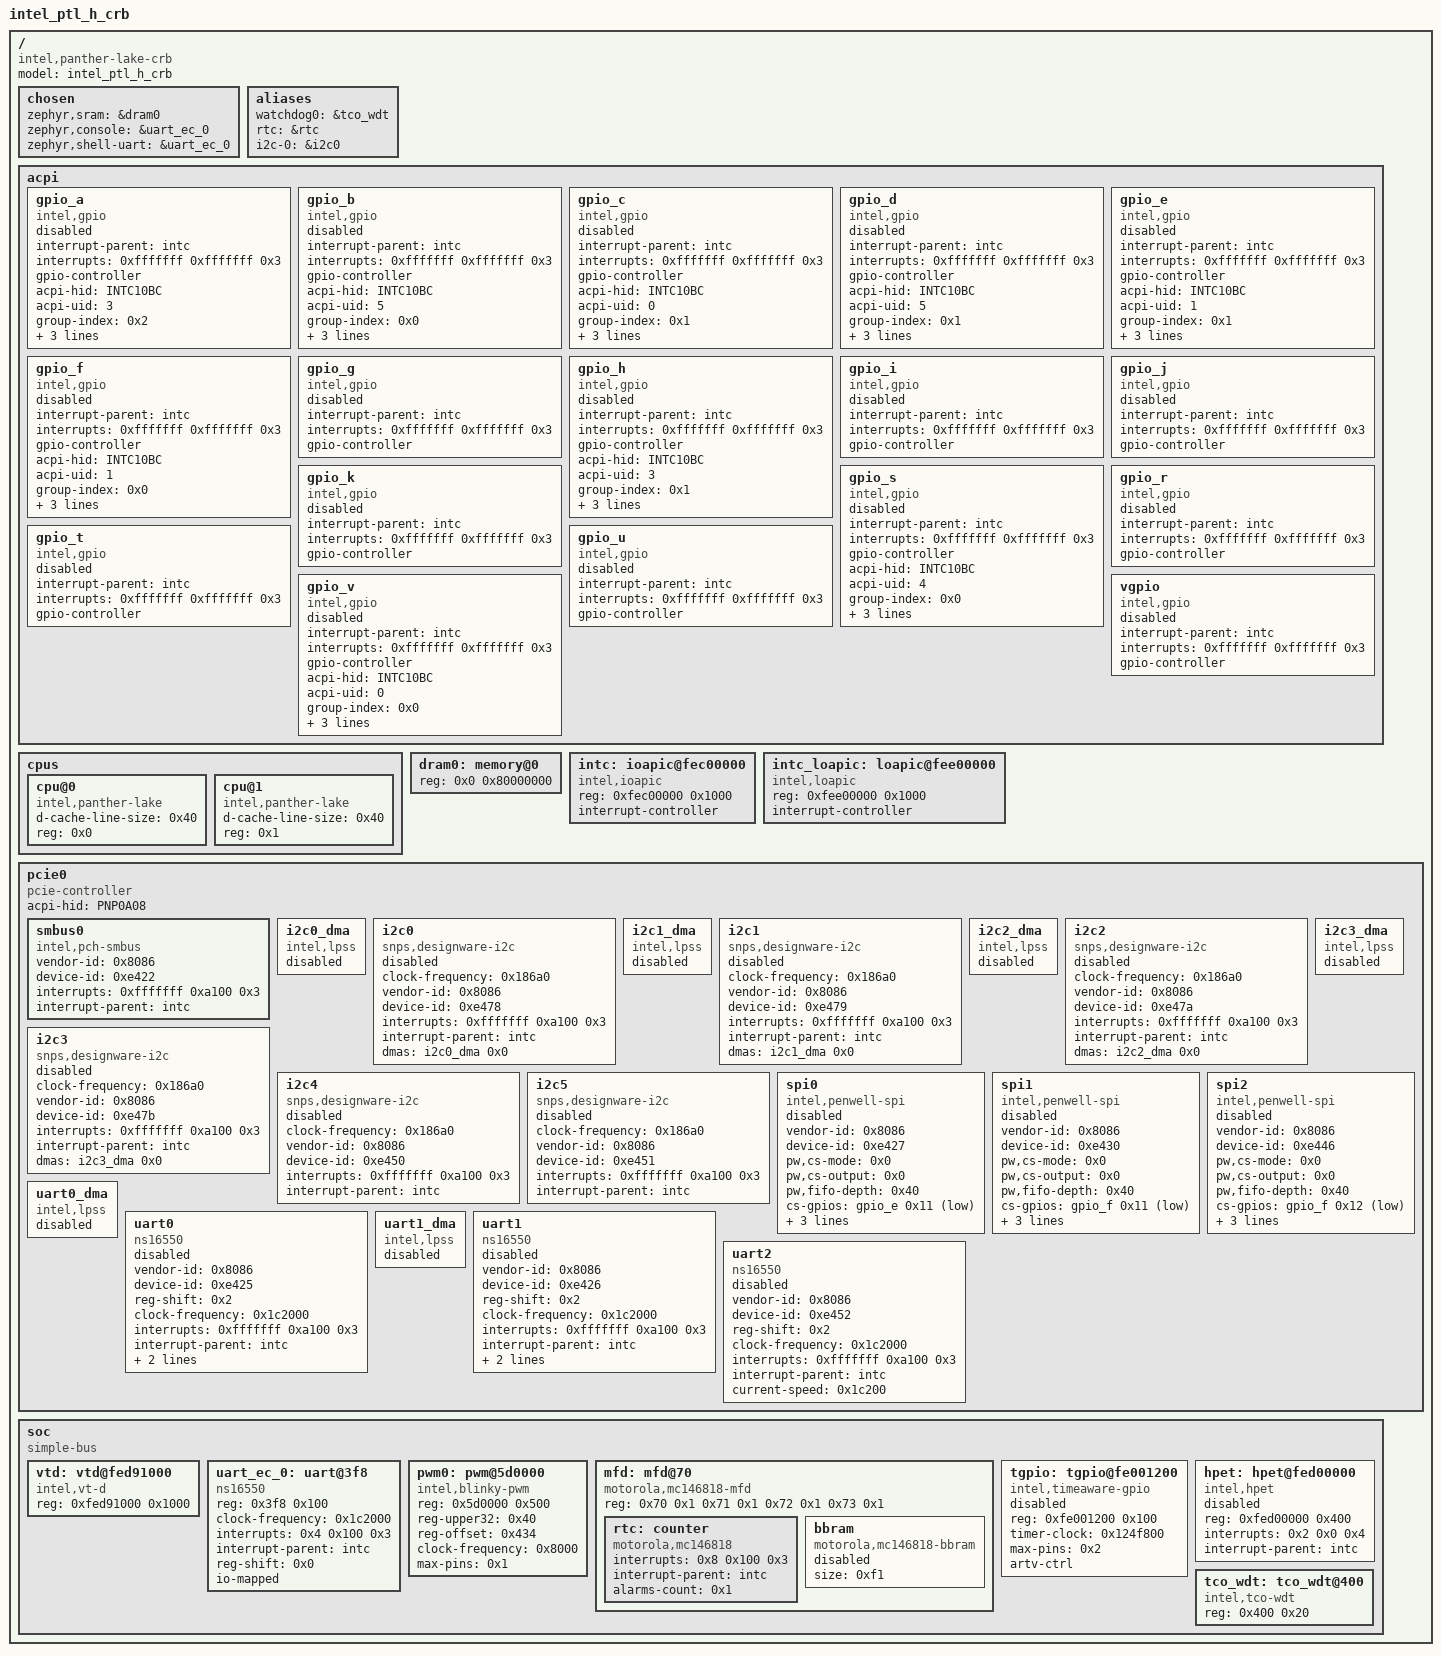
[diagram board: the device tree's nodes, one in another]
/dts-v1/;

/* node '/' defined in zephyr/dts/common/skeleton.dtsi:9 */
/ {
	#address-cells = < 0x1 >;              /* in zephyr/dts/common/skeleton.dtsi:10 */
	#size-cells = < 0x1 >;                 /* in zephyr/dts/common/skeleton.dtsi:11 */
	model = "intel_ptl_h_crb";             /* in zephyr/boards/intel/ptl/intel_ptl_h_crb.dts:15 */
	compatible = "intel,panther-lake-crb"; /* in zephyr/boards/intel/ptl/intel_ptl_h_crb.dts:16 */

	/* node '/chosen' defined in zephyr/dts/common/skeleton.dtsi:13 */
	chosen {
		zephyr,sram = &dram0;           /* in zephyr/boards/intel/ptl/intel_ptl_h_crb.dts:19 */
		zephyr,console = &uart_ec_0;    /* in zephyr/boards/intel/ptl/intel_ptl_h_crb.dts:20 */
		zephyr,shell-uart = &uart_ec_0; /* in zephyr/boards/intel/ptl/intel_ptl_h_crb.dts:21 */
	};

	/* node '/aliases' defined in zephyr/dts/common/skeleton.dtsi:15 */
	aliases {
		watchdog0 = &tco_wdt; /* in zephyr/boards/intel/ptl/intel_ptl_h_crb.dts:25 */
		rtc = &rtc;           /* in zephyr/boards/intel/ptl/intel_ptl_h_crb.dts:26 */
		i2c-0 = &i2c0;        /* in zephyr/boards/intel/ptl/intel_ptl_h_crb.dts:27 */
	};

	/* node '/acpi' defined in zephyr/dts/x86/intel/gpio_common.dtsi:12 */
	acpi {

		/* node '/acpi/gpio_a' defined in zephyr/dts/x86/intel/gpio_common.dtsi:13 */
		gpio_a: gpio_a {
			compatible = "intel,gpio";                /* in zephyr/dts/x86/intel/gpio_common.dtsi:14 */
			interrupt-parent = < &intc >;             /* in zephyr/dts/x86/intel/gpio_common.dtsi:15 */
			interrupts = < 0xfffffff 0xfffffff 0x3 >; /* in zephyr/dts/x86/intel/gpio_common.dtsi:16 */
			gpio-controller;                          /* in zephyr/dts/x86/intel/gpio_common.dtsi:17 */
			#gpio-cells = < 0x2 >;                    /* in zephyr/dts/x86/intel/gpio_common.dtsi:18 */
			acpi-hid = "INTC10BC";                    /* in zephyr/dts/x86/intel/panther_lake_h.dtsi:56 */
			acpi-uid = "3";                           /* in zephyr/dts/x86/intel/panther_lake_h.dtsi:57 */
			group-index = < 0x2 >;                    /* in zephyr/dts/x86/intel/panther_lake_h.dtsi:58 */
			acpi-ginf-3-param;                        /* in zephyr/dts/x86/intel/panther_lake_h.dtsi:59 */
			int-stat-offset = < 0x30 >;               /* in zephyr/dts/x86/intel/panther_lake_h.dtsi:60 */
			int-en-offset = < 0x20 >;                 /* in zephyr/dts/x86/intel/panther_lake_h.dtsi:61 */
			status = "disabled";                      /* in zephyr/dts/x86/intel/panther_lake_h.dtsi:62 */
		};

		/* node '/acpi/gpio_b' defined in zephyr/dts/x86/intel/gpio_common.dtsi:22 */
		gpio_b: gpio_b {
			compatible = "intel,gpio";                /* in zephyr/dts/x86/intel/gpio_common.dtsi:23 */
			interrupt-parent = < &intc >;             /* in zephyr/dts/x86/intel/gpio_common.dtsi:24 */
			interrupts = < 0xfffffff 0xfffffff 0x3 >; /* in zephyr/dts/x86/intel/gpio_common.dtsi:25 */
			gpio-controller;                          /* in zephyr/dts/x86/intel/gpio_common.dtsi:26 */
			#gpio-cells = < 0x2 >;                    /* in zephyr/dts/x86/intel/gpio_common.dtsi:27 */
			acpi-hid = "INTC10BC";                    /* in zephyr/dts/x86/intel/panther_lake_h.dtsi:66 */
			acpi-uid = "5";                           /* in zephyr/dts/x86/intel/panther_lake_h.dtsi:67 */
			group-index = < 0x0 >;                    /* in zephyr/dts/x86/intel/panther_lake_h.dtsi:68 */
			acpi-ginf-3-param;                        /* in zephyr/dts/x86/intel/panther_lake_h.dtsi:69 */
			int-stat-offset = < 0x30 >;               /* in zephyr/dts/x86/intel/panther_lake_h.dtsi:70 */
			int-en-offset = < 0x20 >;                 /* in zephyr/dts/x86/intel/panther_lake_h.dtsi:71 */
			status = "disabled";                      /* in zephyr/dts/x86/intel/panther_lake_h.dtsi:72 */
		};

		/* node '/acpi/gpio_c' defined in zephyr/dts/x86/intel/gpio_common.dtsi:31 */
		gpio_c: gpio_c {
			compatible = "intel,gpio";                /* in zephyr/dts/x86/intel/gpio_common.dtsi:32 */
			interrupt-parent = < &intc >;             /* in zephyr/dts/x86/intel/gpio_common.dtsi:33 */
			interrupts = < 0xfffffff 0xfffffff 0x3 >; /* in zephyr/dts/x86/intel/gpio_common.dtsi:34 */
			gpio-controller;                          /* in zephyr/dts/x86/intel/gpio_common.dtsi:35 */
			#gpio-cells = < 0x2 >;                    /* in zephyr/dts/x86/intel/gpio_common.dtsi:36 */
			acpi-hid = "INTC10BC";                    /* in zephyr/dts/x86/intel/panther_lake_h.dtsi:76 */
			acpi-uid = "0";                           /* in zephyr/dts/x86/intel/panther_lake_h.dtsi:77 */
			group-index = < 0x1 >;                    /* in zephyr/dts/x86/intel/panther_lake_h.dtsi:78 */
			acpi-ginf-3-param;                        /* in zephyr/dts/x86/intel/panther_lake_h.dtsi:79 */
			int-stat-offset = < 0x30 >;               /* in zephyr/dts/x86/intel/panther_lake_h.dtsi:80 */
			int-en-offset = < 0x20 >;                 /* in zephyr/dts/x86/intel/panther_lake_h.dtsi:81 */
			status = "disabled";                      /* in zephyr/dts/x86/intel/panther_lake_h.dtsi:82 */
		};

		/* node '/acpi/gpio_d' defined in zephyr/dts/x86/intel/gpio_common.dtsi:40 */
		gpio_d: gpio_d {
			compatible = "intel,gpio";                /* in zephyr/dts/x86/intel/gpio_common.dtsi:41 */
			interrupt-parent = < &intc >;             /* in zephyr/dts/x86/intel/gpio_common.dtsi:42 */
			interrupts = < 0xfffffff 0xfffffff 0x3 >; /* in zephyr/dts/x86/intel/gpio_common.dtsi:43 */
			gpio-controller;                          /* in zephyr/dts/x86/intel/gpio_common.dtsi:44 */
			#gpio-cells = < 0x2 >;                    /* in zephyr/dts/x86/intel/gpio_common.dtsi:45 */
			acpi-hid = "INTC10BC";                    /* in zephyr/dts/x86/intel/panther_lake_h.dtsi:86 */
			acpi-uid = "5";                           /* in zephyr/dts/x86/intel/panther_lake_h.dtsi:87 */
			group-index = < 0x1 >;                    /* in zephyr/dts/x86/intel/panther_lake_h.dtsi:88 */
			acpi-ginf-3-param;                        /* in zephyr/dts/x86/intel/panther_lake_h.dtsi:89 */
			int-stat-offset = < 0x30 >;               /* in zephyr/dts/x86/intel/panther_lake_h.dtsi:90 */
			int-en-offset = < 0x20 >;                 /* in zephyr/dts/x86/intel/panther_lake_h.dtsi:91 */
			status = "disabled";                      /* in zephyr/dts/x86/intel/panther_lake_h.dtsi:92 */
		};

		/* node '/acpi/gpio_e' defined in zephyr/dts/x86/intel/gpio_common.dtsi:49 */
		gpio_e: gpio_e {
			compatible = "intel,gpio";                /* in zephyr/dts/x86/intel/gpio_common.dtsi:50 */
			interrupt-parent = < &intc >;             /* in zephyr/dts/x86/intel/gpio_common.dtsi:51 */
			interrupts = < 0xfffffff 0xfffffff 0x3 >; /* in zephyr/dts/x86/intel/gpio_common.dtsi:52 */
			gpio-controller;                          /* in zephyr/dts/x86/intel/gpio_common.dtsi:53 */
			#gpio-cells = < 0x2 >;                    /* in zephyr/dts/x86/intel/gpio_common.dtsi:54 */
			acpi-hid = "INTC10BC";                    /* in zephyr/dts/x86/intel/panther_lake_h.dtsi:96 */
			acpi-uid = "1";                           /* in zephyr/dts/x86/intel/panther_lake_h.dtsi:97 */
			group-index = < 0x1 >;                    /* in zephyr/dts/x86/intel/panther_lake_h.dtsi:98 */
			acpi-ginf-3-param;                        /* in zephyr/dts/x86/intel/panther_lake_h.dtsi:99 */
			int-stat-offset = < 0x30 >;               /* in zephyr/dts/x86/intel/panther_lake_h.dtsi:100 */
			int-en-offset = < 0x20 >;                 /* in zephyr/dts/x86/intel/panther_lake_h.dtsi:101 */
			status = "disabled";                      /* in zephyr/dts/x86/intel/panther_lake_h.dtsi:102 */
			phandle = < 0x6 >;                        /* in zephyr/dts/x86/intel/panther_lake_h.dtsi:275 */
		};

		/* node '/acpi/gpio_f' defined in zephyr/dts/x86/intel/gpio_common.dtsi:58 */
		gpio_f: gpio_f {
			compatible = "intel,gpio";                /* in zephyr/dts/x86/intel/gpio_common.dtsi:59 */
			interrupt-parent = < &intc >;             /* in zephyr/dts/x86/intel/gpio_common.dtsi:60 */
			interrupts = < 0xfffffff 0xfffffff 0x3 >; /* in zephyr/dts/x86/intel/gpio_common.dtsi:61 */
			gpio-controller;                          /* in zephyr/dts/x86/intel/gpio_common.dtsi:62 */
			#gpio-cells = < 0x2 >;                    /* in zephyr/dts/x86/intel/gpio_common.dtsi:63 */
			acpi-hid = "INTC10BC";                    /* in zephyr/dts/x86/intel/panther_lake_h.dtsi:106 */
			acpi-uid = "1";                           /* in zephyr/dts/x86/intel/panther_lake_h.dtsi:107 */
			group-index = < 0x0 >;                    /* in zephyr/dts/x86/intel/panther_lake_h.dtsi:108 */
			acpi-ginf-3-param;                        /* in zephyr/dts/x86/intel/panther_lake_h.dtsi:109 */
			int-stat-offset = < 0x30 >;               /* in zephyr/dts/x86/intel/panther_lake_h.dtsi:110 */
			int-en-offset = < 0x20 >;                 /* in zephyr/dts/x86/intel/panther_lake_h.dtsi:111 */
			status = "disabled";                      /* in zephyr/dts/x86/intel/panther_lake_h.dtsi:112 */
			phandle = < 0x7 >;                        /* in zephyr/dts/x86/intel/panther_lake_h.dtsi:291 */
		};

		/* node '/acpi/gpio_g' defined in zephyr/dts/x86/intel/gpio_common.dtsi:67 */
		gpio_g: gpio_g {
			compatible = "intel,gpio";                /* in zephyr/dts/x86/intel/gpio_common.dtsi:68 */
			interrupt-parent = < &intc >;             /* in zephyr/dts/x86/intel/gpio_common.dtsi:69 */
			interrupts = < 0xfffffff 0xfffffff 0x3 >; /* in zephyr/dts/x86/intel/gpio_common.dtsi:70 */
			gpio-controller;                          /* in zephyr/dts/x86/intel/gpio_common.dtsi:71 */
			#gpio-cells = < 0x2 >;                    /* in zephyr/dts/x86/intel/gpio_common.dtsi:72 */
			status = "disabled";                      /* in zephyr/dts/x86/intel/gpio_common.dtsi:73 */
		};

		/* node '/acpi/gpio_h' defined in zephyr/dts/x86/intel/gpio_common.dtsi:76 */
		gpio_h: gpio_h {
			compatible = "intel,gpio";                /* in zephyr/dts/x86/intel/gpio_common.dtsi:77 */
			interrupt-parent = < &intc >;             /* in zephyr/dts/x86/intel/gpio_common.dtsi:78 */
			interrupts = < 0xfffffff 0xfffffff 0x3 >; /* in zephyr/dts/x86/intel/gpio_common.dtsi:79 */
			gpio-controller;                          /* in zephyr/dts/x86/intel/gpio_common.dtsi:80 */
			#gpio-cells = < 0x2 >;                    /* in zephyr/dts/x86/intel/gpio_common.dtsi:81 */
			acpi-hid = "INTC10BC";                    /* in zephyr/dts/x86/intel/panther_lake_h.dtsi:116 */
			acpi-uid = "3";                           /* in zephyr/dts/x86/intel/panther_lake_h.dtsi:117 */
			group-index = < 0x1 >;                    /* in zephyr/dts/x86/intel/panther_lake_h.dtsi:118 */
			acpi-ginf-3-param;                        /* in zephyr/dts/x86/intel/panther_lake_h.dtsi:119 */
			int-stat-offset = < 0x30 >;               /* in zephyr/dts/x86/intel/panther_lake_h.dtsi:120 */
			int-en-offset = < 0x20 >;                 /* in zephyr/dts/x86/intel/panther_lake_h.dtsi:121 */
			status = "disabled";                      /* in zephyr/dts/x86/intel/panther_lake_h.dtsi:122 */
		};

		/* node '/acpi/gpio_i' defined in zephyr/dts/x86/intel/gpio_common.dtsi:85 */
		gpio_i: gpio_i {
			compatible = "intel,gpio";                /* in zephyr/dts/x86/intel/gpio_common.dtsi:86 */
			interrupt-parent = < &intc >;             /* in zephyr/dts/x86/intel/gpio_common.dtsi:87 */
			interrupts = < 0xfffffff 0xfffffff 0x3 >; /* in zephyr/dts/x86/intel/gpio_common.dtsi:88 */
			gpio-controller;                          /* in zephyr/dts/x86/intel/gpio_common.dtsi:89 */
			#gpio-cells = < 0x2 >;                    /* in zephyr/dts/x86/intel/gpio_common.dtsi:90 */
			status = "disabled";                      /* in zephyr/dts/x86/intel/gpio_common.dtsi:91 */
		};

		/* node '/acpi/gpio_j' defined in zephyr/dts/x86/intel/gpio_common.dtsi:94 */
		gpio_j: gpio_j {
			compatible = "intel,gpio";                /* in zephyr/dts/x86/intel/gpio_common.dtsi:95 */
			interrupt-parent = < &intc >;             /* in zephyr/dts/x86/intel/gpio_common.dtsi:96 */
			interrupts = < 0xfffffff 0xfffffff 0x3 >; /* in zephyr/dts/x86/intel/gpio_common.dtsi:97 */
			gpio-controller;                          /* in zephyr/dts/x86/intel/gpio_common.dtsi:98 */
			#gpio-cells = < 0x2 >;                    /* in zephyr/dts/x86/intel/gpio_common.dtsi:99 */
			status = "disabled";                      /* in zephyr/dts/x86/intel/gpio_common.dtsi:100 */
		};

		/* node '/acpi/gpio_k' defined in zephyr/dts/x86/intel/gpio_common.dtsi:103 */
		gpio_k: gpio_k {
			compatible = "intel,gpio";                /* in zephyr/dts/x86/intel/gpio_common.dtsi:104 */
			interrupt-parent = < &intc >;             /* in zephyr/dts/x86/intel/gpio_common.dtsi:105 */
			interrupts = < 0xfffffff 0xfffffff 0x3 >; /* in zephyr/dts/x86/intel/gpio_common.dtsi:106 */
			gpio-controller;                          /* in zephyr/dts/x86/intel/gpio_common.dtsi:107 */
			#gpio-cells = < 0x2 >;                    /* in zephyr/dts/x86/intel/gpio_common.dtsi:108 */
			status = "disabled";                      /* in zephyr/dts/x86/intel/gpio_common.dtsi:109 */
		};

		/* node '/acpi/gpio_s' defined in zephyr/dts/x86/intel/gpio_common.dtsi:112 */
		gpio_s: gpio_s {
			compatible = "intel,gpio";                /* in zephyr/dts/x86/intel/gpio_common.dtsi:113 */
			interrupt-parent = < &intc >;             /* in zephyr/dts/x86/intel/gpio_common.dtsi:114 */
			interrupts = < 0xfffffff 0xfffffff 0x3 >; /* in zephyr/dts/x86/intel/gpio_common.dtsi:115 */
			gpio-controller;                          /* in zephyr/dts/x86/intel/gpio_common.dtsi:116 */
			#gpio-cells = < 0x2 >;                    /* in zephyr/dts/x86/intel/gpio_common.dtsi:117 */
			acpi-hid = "INTC10BC";                    /* in zephyr/dts/x86/intel/panther_lake_h.dtsi:126 */
			acpi-uid = "4";                           /* in zephyr/dts/x86/intel/panther_lake_h.dtsi:127 */
			group-index = < 0x0 >;                    /* in zephyr/dts/x86/intel/panther_lake_h.dtsi:128 */
			acpi-ginf-3-param;                        /* in zephyr/dts/x86/intel/panther_lake_h.dtsi:129 */
			int-stat-offset = < 0x30 >;               /* in zephyr/dts/x86/intel/panther_lake_h.dtsi:130 */
			int-en-offset = < 0x20 >;                 /* in zephyr/dts/x86/intel/panther_lake_h.dtsi:131 */
			status = "disabled";                      /* in zephyr/dts/x86/intel/panther_lake_h.dtsi:132 */
		};

		/* node '/acpi/gpio_r' defined in zephyr/dts/x86/intel/gpio_common.dtsi:121 */
		gpio_r: gpio_r {
			compatible = "intel,gpio";                /* in zephyr/dts/x86/intel/gpio_common.dtsi:122 */
			interrupt-parent = < &intc >;             /* in zephyr/dts/x86/intel/gpio_common.dtsi:123 */
			interrupts = < 0xfffffff 0xfffffff 0x3 >; /* in zephyr/dts/x86/intel/gpio_common.dtsi:124 */
			gpio-controller;                          /* in zephyr/dts/x86/intel/gpio_common.dtsi:125 */
			#gpio-cells = < 0x2 >;                    /* in zephyr/dts/x86/intel/gpio_common.dtsi:126 */
			status = "disabled";                      /* in zephyr/dts/x86/intel/gpio_common.dtsi:127 */
		};

		/* node '/acpi/gpio_t' defined in zephyr/dts/x86/intel/gpio_common.dtsi:130 */
		gpio_t: gpio_t {
			compatible = "intel,gpio";                /* in zephyr/dts/x86/intel/gpio_common.dtsi:131 */
			interrupt-parent = < &intc >;             /* in zephyr/dts/x86/intel/gpio_common.dtsi:132 */
			interrupts = < 0xfffffff 0xfffffff 0x3 >; /* in zephyr/dts/x86/intel/gpio_common.dtsi:133 */
			gpio-controller;                          /* in zephyr/dts/x86/intel/gpio_common.dtsi:134 */
			#gpio-cells = < 0x2 >;                    /* in zephyr/dts/x86/intel/gpio_common.dtsi:135 */
			status = "disabled";                      /* in zephyr/dts/x86/intel/gpio_common.dtsi:136 */
		};

		/* node '/acpi/gpio_u' defined in zephyr/dts/x86/intel/gpio_common.dtsi:139 */
		gpio_u: gpio_u {
			compatible = "intel,gpio";                /* in zephyr/dts/x86/intel/gpio_common.dtsi:140 */
			interrupt-parent = < &intc >;             /* in zephyr/dts/x86/intel/gpio_common.dtsi:141 */
			interrupts = < 0xfffffff 0xfffffff 0x3 >; /* in zephyr/dts/x86/intel/gpio_common.dtsi:142 */
			gpio-controller;                          /* in zephyr/dts/x86/intel/gpio_common.dtsi:143 */
			#gpio-cells = < 0x2 >;                    /* in zephyr/dts/x86/intel/gpio_common.dtsi:144 */
			status = "disabled";                      /* in zephyr/dts/x86/intel/gpio_common.dtsi:145 */
		};

		/* node '/acpi/gpio_v' defined in zephyr/dts/x86/intel/gpio_common.dtsi:148 */
		gpio_v: gpio_v {
			compatible = "intel,gpio";                /* in zephyr/dts/x86/intel/gpio_common.dtsi:149 */
			interrupt-parent = < &intc >;             /* in zephyr/dts/x86/intel/gpio_common.dtsi:150 */
			interrupts = < 0xfffffff 0xfffffff 0x3 >; /* in zephyr/dts/x86/intel/gpio_common.dtsi:151 */
			gpio-controller;                          /* in zephyr/dts/x86/intel/gpio_common.dtsi:152 */
			#gpio-cells = < 0x2 >;                    /* in zephyr/dts/x86/intel/gpio_common.dtsi:153 */
			acpi-hid = "INTC10BC";                    /* in zephyr/dts/x86/intel/panther_lake_h.dtsi:136 */
			acpi-uid = "0";                           /* in zephyr/dts/x86/intel/panther_lake_h.dtsi:137 */
			group-index = < 0x0 >;                    /* in zephyr/dts/x86/intel/panther_lake_h.dtsi:138 */
			acpi-ginf-3-param;                        /* in zephyr/dts/x86/intel/panther_lake_h.dtsi:139 */
			int-stat-offset = < 0x30 >;               /* in zephyr/dts/x86/intel/panther_lake_h.dtsi:140 */
			int-en-offset = < 0x20 >;                 /* in zephyr/dts/x86/intel/panther_lake_h.dtsi:141 */
			status = "disabled";                      /* in zephyr/dts/x86/intel/panther_lake_h.dtsi:142 */
		};

		/* node '/acpi/vgpio' defined in zephyr/dts/x86/intel/gpio_common.dtsi:157 */
		vgpio: vgpio {
			compatible = "intel,gpio";                /* in zephyr/dts/x86/intel/gpio_common.dtsi:158 */
			interrupt-parent = < &intc >;             /* in zephyr/dts/x86/intel/gpio_common.dtsi:159 */
			interrupts = < 0xfffffff 0xfffffff 0x3 >; /* in zephyr/dts/x86/intel/gpio_common.dtsi:160 */
			gpio-controller;                          /* in zephyr/dts/x86/intel/gpio_common.dtsi:161 */
			#gpio-cells = < 0x2 >;                    /* in zephyr/dts/x86/intel/gpio_common.dtsi:162 */
			status = "disabled";                      /* in zephyr/dts/x86/intel/gpio_common.dtsi:163 */
		};
	};

	/* node '/cpus' defined in zephyr/dts/x86/intel/panther_lake_h.dtsi:14 */
	cpus {
		#address-cells = < 0x1 >; /* in zephyr/dts/x86/intel/panther_lake_h.dtsi:15 */
		#size-cells = < 0x0 >;    /* in zephyr/dts/x86/intel/panther_lake_h.dtsi:16 */

		/* node '/cpus/cpu@0' defined in zephyr/dts/x86/intel/panther_lake_h.dtsi:18 */
		cpu@0 {
			device_type = "cpu";               /* in zephyr/dts/x86/intel/panther_lake_h.dtsi:19 */
			compatible = "intel,panther-lake"; /* in zephyr/dts/x86/intel/panther_lake_h.dtsi:20 */
			d-cache-line-size = < 0x40 >;      /* in zephyr/dts/x86/intel/panther_lake_h.dtsi:21 */
			reg = < 0x0 >;                     /* in zephyr/dts/x86/intel/panther_lake_h.dtsi:22 */
		};

		/* node '/cpus/cpu@1' defined in zephyr/dts/x86/intel/panther_lake_h.dtsi:25 */
		cpu@1 {
			device_type = "cpu";               /* in zephyr/dts/x86/intel/panther_lake_h.dtsi:26 */
			compatible = "intel,panther-lake"; /* in zephyr/dts/x86/intel/panther_lake_h.dtsi:27 */
			d-cache-line-size = < 0x40 >;      /* in zephyr/dts/x86/intel/panther_lake_h.dtsi:28 */
			reg = < 0x1 >;                     /* in zephyr/dts/x86/intel/panther_lake_h.dtsi:29 */
		};
	};

	/* node '/memory@0' defined in zephyr/dts/x86/intel/panther_lake_h.dtsi:33 */
	dram0: memory@0 {
		device_type = "memory";   /* in zephyr/dts/x86/intel/panther_lake_h.dtsi:34 */
		reg = < 0x0 0x80000000 >; /* in zephyr/dts/x86/intel/panther_lake_h.dtsi:35 */
	};

	/* node '/ioapic@fec00000' defined in zephyr/dts/x86/intel/panther_lake_h.dtsi:38 */
	intc: ioapic@fec00000 {
		compatible = "intel,ioapic"; /* in zephyr/dts/x86/intel/panther_lake_h.dtsi:39 */
		#address-cells = < 0x1 >;    /* in zephyr/dts/x86/intel/panther_lake_h.dtsi:40 */
		#interrupt-cells = < 0x3 >;  /* in zephyr/dts/x86/intel/panther_lake_h.dtsi:41 */
		reg = < 0xfec00000 0x1000 >; /* in zephyr/dts/x86/intel/panther_lake_h.dtsi:42 */
		interrupt-controller;        /* in zephyr/dts/x86/intel/panther_lake_h.dtsi:43 */
		phandle = < 0x1 >;           /* in zephyr/dts/x86/intel/gpio_common.dtsi:15 */
	};

	/* node '/loapic@fee00000' defined in zephyr/dts/x86/intel/panther_lake_h.dtsi:46 */
	intc_loapic: loapic@fee00000 {
		compatible = "intel,loapic"; /* in zephyr/dts/x86/intel/panther_lake_h.dtsi:47 */
		reg = < 0xfee00000 0x1000 >; /* in zephyr/dts/x86/intel/panther_lake_h.dtsi:48 */
		interrupt-controller;        /* in zephyr/dts/x86/intel/panther_lake_h.dtsi:49 */
		#interrupt-cells = < 0x3 >;  /* in zephyr/dts/x86/intel/panther_lake_h.dtsi:50 */
		#address-cells = < 0x1 >;    /* in zephyr/dts/x86/intel/panther_lake_h.dtsi:51 */
	};

	/* node '/pcie0' defined in zephyr/dts/x86/intel/panther_lake_h.dtsi:146 */
	pcie0: pcie0 {
		#address-cells = < 0x1 >;       /* in zephyr/dts/x86/intel/panther_lake_h.dtsi:147 */
		#size-cells = < 0x1 >;          /* in zephyr/dts/x86/intel/panther_lake_h.dtsi:148 */
		compatible = "pcie-controller"; /* in zephyr/dts/x86/intel/panther_lake_h.dtsi:149 */
		acpi-hid = "PNP0A08";           /* in zephyr/dts/x86/intel/panther_lake_h.dtsi:150 */
		ranges;                         /* in zephyr/dts/x86/intel/panther_lake_h.dtsi:151 */

		/* node '/pcie0/smbus0' defined in zephyr/dts/x86/intel/panther_lake_h.dtsi:153 */
		smbus0: smbus0 {
			compatible = "intel,pch-smbus";        /* in zephyr/dts/x86/intel/panther_lake_h.dtsi:154 */
			#address-cells = < 0x1 >;              /* in zephyr/dts/x86/intel/panther_lake_h.dtsi:155 */
			#size-cells = < 0x0 >;                 /* in zephyr/dts/x86/intel/panther_lake_h.dtsi:156 */
			vendor-id = < 0x8086 >;                /* in zephyr/dts/x86/intel/panther_lake_h.dtsi:157 */
			device-id = < 0xe422 >;                /* in zephyr/dts/x86/intel/panther_lake_h.dtsi:158 */
			interrupts = < 0xfffffff 0xa100 0x3 >; /* in zephyr/dts/x86/intel/panther_lake_h.dtsi:159 */
			interrupt-parent = < &intc >;          /* in zephyr/dts/x86/intel/panther_lake_h.dtsi:160 */
			status = "okay";                       /* in zephyr/boards/intel/ptl/intel_ptl_h_crb.dts:44 */
		};

		/* node '/pcie0/i2c0_dma' defined in zephyr/dts/x86/intel/panther_lake_h.dtsi:164 */
		i2c0_dma: i2c0_dma {
			compatible = "intel,lpss"; /* in zephyr/dts/x86/intel/panther_lake_h.dtsi:165 */
			#dma-cells = < 0x1 >;      /* in zephyr/dts/x86/intel/panther_lake_h.dtsi:166 */
			status = "disabled";       /* in zephyr/dts/x86/intel/panther_lake_h.dtsi:167 */
			phandle = < 0x2 >;         /* in zephyr/dts/x86/intel/panther_lake_h.dtsi:179 */
		};

		/* node '/pcie0/i2c0' defined in zephyr/dts/x86/intel/panther_lake_h.dtsi:170 */
		i2c0: i2c0 {
			compatible = "snps,designware-i2c";    /* in zephyr/dts/x86/intel/panther_lake_h.dtsi:171 */
			clock-frequency = < 0x186a0 >;         /* in zephyr/dts/x86/intel/panther_lake_h.dtsi:172 */
			#address-cells = < 0x1 >;              /* in zephyr/dts/x86/intel/panther_lake_h.dtsi:173 */
			#size-cells = < 0x0 >;                 /* in zephyr/dts/x86/intel/panther_lake_h.dtsi:174 */
			vendor-id = < 0x8086 >;                /* in zephyr/dts/x86/intel/panther_lake_h.dtsi:175 */
			device-id = < 0xe478 >;                /* in zephyr/dts/x86/intel/panther_lake_h.dtsi:176 */
			interrupts = < 0xfffffff 0xa100 0x3 >; /* in zephyr/dts/x86/intel/panther_lake_h.dtsi:177 */
			interrupt-parent = < &intc >;          /* in zephyr/dts/x86/intel/panther_lake_h.dtsi:178 */
			dmas = < &i2c0_dma 0x0 >;              /* in zephyr/dts/x86/intel/panther_lake_h.dtsi:179 */
			status = "disabled";                   /* in zephyr/dts/x86/intel/panther_lake_h.dtsi:180 */
		};

		/* node '/pcie0/i2c1_dma' defined in zephyr/dts/x86/intel/panther_lake_h.dtsi:183 */
		i2c1_dma: i2c1_dma {
			compatible = "intel,lpss"; /* in zephyr/dts/x86/intel/panther_lake_h.dtsi:184 */
			#dma-cells = < 0x1 >;      /* in zephyr/dts/x86/intel/panther_lake_h.dtsi:185 */
			status = "disabled";       /* in zephyr/dts/x86/intel/panther_lake_h.dtsi:186 */
			phandle = < 0x3 >;         /* in zephyr/dts/x86/intel/panther_lake_h.dtsi:198 */
		};

		/* node '/pcie0/i2c1' defined in zephyr/dts/x86/intel/panther_lake_h.dtsi:189 */
		i2c1: i2c1 {
			compatible = "snps,designware-i2c";    /* in zephyr/dts/x86/intel/panther_lake_h.dtsi:190 */
			clock-frequency = < 0x186a0 >;         /* in zephyr/dts/x86/intel/panther_lake_h.dtsi:191 */
			#address-cells = < 0x1 >;              /* in zephyr/dts/x86/intel/panther_lake_h.dtsi:192 */
			#size-cells = < 0x0 >;                 /* in zephyr/dts/x86/intel/panther_lake_h.dtsi:193 */
			vendor-id = < 0x8086 >;                /* in zephyr/dts/x86/intel/panther_lake_h.dtsi:194 */
			device-id = < 0xe479 >;                /* in zephyr/dts/x86/intel/panther_lake_h.dtsi:195 */
			interrupts = < 0xfffffff 0xa100 0x3 >; /* in zephyr/dts/x86/intel/panther_lake_h.dtsi:196 */
			interrupt-parent = < &intc >;          /* in zephyr/dts/x86/intel/panther_lake_h.dtsi:197 */
			dmas = < &i2c1_dma 0x0 >;              /* in zephyr/dts/x86/intel/panther_lake_h.dtsi:198 */
			status = "disabled";                   /* in zephyr/dts/x86/intel/panther_lake_h.dtsi:199 */
		};

		/* node '/pcie0/i2c2_dma' defined in zephyr/dts/x86/intel/panther_lake_h.dtsi:202 */
		i2c2_dma: i2c2_dma {
			compatible = "intel,lpss"; /* in zephyr/dts/x86/intel/panther_lake_h.dtsi:203 */
			#dma-cells = < 0x1 >;      /* in zephyr/dts/x86/intel/panther_lake_h.dtsi:204 */
			status = "disabled";       /* in zephyr/dts/x86/intel/panther_lake_h.dtsi:205 */
			phandle = < 0x4 >;         /* in zephyr/dts/x86/intel/panther_lake_h.dtsi:219 */
		};

		/* node '/pcie0/i2c2' defined in zephyr/dts/x86/intel/panther_lake_h.dtsi:208 */
		i2c2: i2c2 {
			compatible = "snps,designware-i2c";    /* in zephyr/dts/x86/intel/panther_lake_h.dtsi:209 */
			clock-frequency = < 0x186a0 >;         /* in zephyr/dts/x86/intel/panther_lake_h.dtsi:210 */
			#address-cells = < 0x1 >;              /* in zephyr/dts/x86/intel/panther_lake_h.dtsi:213 */
			#size-cells = < 0x0 >;                 /* in zephyr/dts/x86/intel/panther_lake_h.dtsi:214 */
			vendor-id = < 0x8086 >;                /* in zephyr/dts/x86/intel/panther_lake_h.dtsi:215 */
			device-id = < 0xe47a >;                /* in zephyr/dts/x86/intel/panther_lake_h.dtsi:216 */
			interrupts = < 0xfffffff 0xa100 0x3 >; /* in zephyr/dts/x86/intel/panther_lake_h.dtsi:217 */
			interrupt-parent = < &intc >;          /* in zephyr/dts/x86/intel/panther_lake_h.dtsi:218 */
			dmas = < &i2c2_dma 0x0 >;              /* in zephyr/dts/x86/intel/panther_lake_h.dtsi:219 */
			status = "disabled";                   /* in zephyr/dts/x86/intel/panther_lake_h.dtsi:220 */
		};

		/* node '/pcie0/i2c3_dma' defined in zephyr/dts/x86/intel/panther_lake_h.dtsi:223 */
		i2c3_dma: i2c3_dma {
			compatible = "intel,lpss"; /* in zephyr/dts/x86/intel/panther_lake_h.dtsi:224 */
			#dma-cells = < 0x1 >;      /* in zephyr/dts/x86/intel/panther_lake_h.dtsi:225 */
			status = "disabled";       /* in zephyr/dts/x86/intel/panther_lake_h.dtsi:226 */
			phandle = < 0x5 >;         /* in zephyr/dts/x86/intel/panther_lake_h.dtsi:238 */
		};

		/* node '/pcie0/i2c3' defined in zephyr/dts/x86/intel/panther_lake_h.dtsi:229 */
		i2c3: i2c3 {
			compatible = "snps,designware-i2c";    /* in zephyr/dts/x86/intel/panther_lake_h.dtsi:230 */
			clock-frequency = < 0x186a0 >;         /* in zephyr/dts/x86/intel/panther_lake_h.dtsi:231 */
			#address-cells = < 0x1 >;              /* in zephyr/dts/x86/intel/panther_lake_h.dtsi:232 */
			#size-cells = < 0x0 >;                 /* in zephyr/dts/x86/intel/panther_lake_h.dtsi:233 */
			vendor-id = < 0x8086 >;                /* in zephyr/dts/x86/intel/panther_lake_h.dtsi:234 */
			device-id = < 0xe47b >;                /* in zephyr/dts/x86/intel/panther_lake_h.dtsi:235 */
			interrupts = < 0xfffffff 0xa100 0x3 >; /* in zephyr/dts/x86/intel/panther_lake_h.dtsi:236 */
			interrupt-parent = < &intc >;          /* in zephyr/dts/x86/intel/panther_lake_h.dtsi:237 */
			dmas = < &i2c3_dma 0x0 >;              /* in zephyr/dts/x86/intel/panther_lake_h.dtsi:238 */
			status = "disabled";                   /* in zephyr/dts/x86/intel/panther_lake_h.dtsi:239 */
		};

		/* node '/pcie0/i2c4' defined in zephyr/dts/x86/intel/panther_lake_h.dtsi:242 */
		i2c4: i2c4 {
			compatible = "snps,designware-i2c";    /* in zephyr/dts/x86/intel/panther_lake_h.dtsi:243 */
			clock-frequency = < 0x186a0 >;         /* in zephyr/dts/x86/intel/panther_lake_h.dtsi:244 */
			#address-cells = < 0x1 >;              /* in zephyr/dts/x86/intel/panther_lake_h.dtsi:245 */
			#size-cells = < 0x0 >;                 /* in zephyr/dts/x86/intel/panther_lake_h.dtsi:246 */
			vendor-id = < 0x8086 >;                /* in zephyr/dts/x86/intel/panther_lake_h.dtsi:247 */
			device-id = < 0xe450 >;                /* in zephyr/dts/x86/intel/panther_lake_h.dtsi:248 */
			interrupts = < 0xfffffff 0xa100 0x3 >; /* in zephyr/dts/x86/intel/panther_lake_h.dtsi:249 */
			interrupt-parent = < &intc >;          /* in zephyr/dts/x86/intel/panther_lake_h.dtsi:250 */
			status = "disabled";                   /* in zephyr/dts/x86/intel/panther_lake_h.dtsi:251 */
		};

		/* node '/pcie0/i2c5' defined in zephyr/dts/x86/intel/panther_lake_h.dtsi:254 */
		i2c5: i2c5 {
			compatible = "snps,designware-i2c";    /* in zephyr/dts/x86/intel/panther_lake_h.dtsi:255 */
			clock-frequency = < 0x186a0 >;         /* in zephyr/dts/x86/intel/panther_lake_h.dtsi:256 */
			#address-cells = < 0x1 >;              /* in zephyr/dts/x86/intel/panther_lake_h.dtsi:257 */
			#size-cells = < 0x0 >;                 /* in zephyr/dts/x86/intel/panther_lake_h.dtsi:258 */
			vendor-id = < 0x8086 >;                /* in zephyr/dts/x86/intel/panther_lake_h.dtsi:259 */
			device-id = < 0xe451 >;                /* in zephyr/dts/x86/intel/panther_lake_h.dtsi:260 */
			interrupts = < 0xfffffff 0xa100 0x3 >; /* in zephyr/dts/x86/intel/panther_lake_h.dtsi:261 */
			interrupt-parent = < &intc >;          /* in zephyr/dts/x86/intel/panther_lake_h.dtsi:262 */
			status = "disabled";                   /* in zephyr/dts/x86/intel/panther_lake_h.dtsi:263 */
		};

		/* node '/pcie0/spi0' defined in zephyr/dts/x86/intel/panther_lake_h.dtsi:266 */
		spi0: spi0 {
			compatible = "intel,penwell-spi";      /* in zephyr/dts/x86/intel/panther_lake_h.dtsi:267 */
			vendor-id = < 0x8086 >;                /* in zephyr/dts/x86/intel/panther_lake_h.dtsi:268 */
			device-id = < 0xe427 >;                /* in zephyr/dts/x86/intel/panther_lake_h.dtsi:269 */
			#address-cells = < 0x1 >;              /* in zephyr/dts/x86/intel/panther_lake_h.dtsi:270 */
			#size-cells = < 0x0 >;                 /* in zephyr/dts/x86/intel/panther_lake_h.dtsi:271 */
			pw,cs-mode = < 0x0 >;                  /* in zephyr/dts/x86/intel/panther_lake_h.dtsi:272 */
			pw,cs-output = < 0x0 >;                /* in zephyr/dts/x86/intel/panther_lake_h.dtsi:273 */
			pw,fifo-depth = < 0x40 >;              /* in zephyr/dts/x86/intel/panther_lake_h.dtsi:274 */
			cs-gpios = < &gpio_e 0x11 0x1 >;       /* in zephyr/dts/x86/intel/panther_lake_h.dtsi:275 */
			clock-frequency = < 0x5f5e100 >;       /* in zephyr/dts/x86/intel/panther_lake_h.dtsi:276 */
			interrupts = < 0xfffffff 0xa100 0x3 >; /* in zephyr/dts/x86/intel/panther_lake_h.dtsi:277 */
			interrupt-parent = < &intc >;          /* in zephyr/dts/x86/intel/panther_lake_h.dtsi:278 */
			status = "disabled";                   /* in zephyr/dts/x86/intel/panther_lake_h.dtsi:279 */
		};

		/* node '/pcie0/spi1' defined in zephyr/dts/x86/intel/panther_lake_h.dtsi:282 */
		spi1: spi1 {
			compatible = "intel,penwell-spi";      /* in zephyr/dts/x86/intel/panther_lake_h.dtsi:283 */
			vendor-id = < 0x8086 >;                /* in zephyr/dts/x86/intel/panther_lake_h.dtsi:284 */
			device-id = < 0xe430 >;                /* in zephyr/dts/x86/intel/panther_lake_h.dtsi:285 */
			#address-cells = < 0x1 >;              /* in zephyr/dts/x86/intel/panther_lake_h.dtsi:286 */
			#size-cells = < 0x0 >;                 /* in zephyr/dts/x86/intel/panther_lake_h.dtsi:287 */
			pw,cs-mode = < 0x0 >;                  /* in zephyr/dts/x86/intel/panther_lake_h.dtsi:288 */
			pw,cs-output = < 0x0 >;                /* in zephyr/dts/x86/intel/panther_lake_h.dtsi:289 */
			pw,fifo-depth = < 0x40 >;              /* in zephyr/dts/x86/intel/panther_lake_h.dtsi:290 */
			cs-gpios = < &gpio_f 0x11 0x1 >;       /* in zephyr/dts/x86/intel/panther_lake_h.dtsi:291 */
			clock-frequency = < 0x5f5e100 >;       /* in zephyr/dts/x86/intel/panther_lake_h.dtsi:292 */
			interrupts = < 0xfffffff 0xa100 0x3 >; /* in zephyr/dts/x86/intel/panther_lake_h.dtsi:293 */
			interrupt-parent = < &intc >;          /* in zephyr/dts/x86/intel/panther_lake_h.dtsi:294 */
			status = "disabled";                   /* in zephyr/dts/x86/intel/panther_lake_h.dtsi:295 */
		};

		/* node '/pcie0/spi2' defined in zephyr/dts/x86/intel/panther_lake_h.dtsi:298 */
		spi2: spi2 {
			compatible = "intel,penwell-spi";      /* in zephyr/dts/x86/intel/panther_lake_h.dtsi:299 */
			vendor-id = < 0x8086 >;                /* in zephyr/dts/x86/intel/panther_lake_h.dtsi:300 */
			device-id = < 0xe446 >;                /* in zephyr/dts/x86/intel/panther_lake_h.dtsi:301 */
			#address-cells = < 0x1 >;              /* in zephyr/dts/x86/intel/panther_lake_h.dtsi:302 */
			#size-cells = < 0x0 >;                 /* in zephyr/dts/x86/intel/panther_lake_h.dtsi:303 */
			pw,cs-mode = < 0x0 >;                  /* in zephyr/dts/x86/intel/panther_lake_h.dtsi:304 */
			pw,cs-output = < 0x0 >;                /* in zephyr/dts/x86/intel/panther_lake_h.dtsi:305 */
			pw,fifo-depth = < 0x40 >;              /* in zephyr/dts/x86/intel/panther_lake_h.dtsi:306 */
			cs-gpios = < &gpio_f 0x12 0x1 >;       /* in zephyr/dts/x86/intel/panther_lake_h.dtsi:307 */
			clock-frequency = < 0x5f5e100 >;       /* in zephyr/dts/x86/intel/panther_lake_h.dtsi:308 */
			interrupts = < 0xfffffff 0xa100 0x3 >; /* in zephyr/dts/x86/intel/panther_lake_h.dtsi:309 */
			interrupt-parent = < &intc >;          /* in zephyr/dts/x86/intel/panther_lake_h.dtsi:310 */
			status = "disabled";                   /* in zephyr/dts/x86/intel/panther_lake_h.dtsi:311 */
		};

		/* node '/pcie0/uart0_dma' defined in zephyr/dts/x86/intel/panther_lake_h.dtsi:314 */
		uart0_dma: uart0_dma {
			compatible = "intel,lpss"; /* in zephyr/dts/x86/intel/panther_lake_h.dtsi:315 */
			#dma-cells = < 0x1 >;      /* in zephyr/dts/x86/intel/panther_lake_h.dtsi:316 */
			status = "disabled";       /* in zephyr/dts/x86/intel/panther_lake_h.dtsi:317 */
			phandle = < 0x8 >;         /* in zephyr/dts/x86/intel/panther_lake_h.dtsi:329 */
		};

		/* node '/pcie0/uart0' defined in zephyr/dts/x86/intel/panther_lake_h.dtsi:320 */
		uart0: uart0 {
			compatible = "ns16550";                /* in zephyr/dts/x86/intel/panther_lake_h.dtsi:321 */
			vendor-id = < 0x8086 >;                /* in zephyr/dts/x86/intel/panther_lake_h.dtsi:322 */
			device-id = < 0xe425 >;                /* in zephyr/dts/x86/intel/panther_lake_h.dtsi:323 */
			reg-shift = < 0x2 >;                   /* in zephyr/dts/x86/intel/panther_lake_h.dtsi:324 */
			clock-frequency = < 0x1c2000 >;        /* in zephyr/dts/x86/intel/panther_lake_h.dtsi:325 */
			interrupts = < 0xfffffff 0xa100 0x3 >; /* in zephyr/dts/x86/intel/panther_lake_h.dtsi:326 */
			interrupt-parent = < &intc >;          /* in zephyr/dts/x86/intel/panther_lake_h.dtsi:327 */
			current-speed = < 0x1c200 >;           /* in zephyr/dts/x86/intel/panther_lake_h.dtsi:328 */
			dmas = < &uart0_dma 0x0 >,
			       < &uart0_dma 0x1 >;             /* in zephyr/dts/x86/intel/panther_lake_h.dtsi:329 */
			dma-names = "tx",
			            "rx";                      /* in zephyr/dts/x86/intel/panther_lake_h.dtsi:330 */
			status = "disabled";                   /* in zephyr/dts/x86/intel/panther_lake_h.dtsi:331 */
		};

		/* node '/pcie0/uart1_dma' defined in zephyr/dts/x86/intel/panther_lake_h.dtsi:334 */
		uart1_dma: uart1_dma {
			compatible = "intel,lpss"; /* in zephyr/dts/x86/intel/panther_lake_h.dtsi:335 */
			#dma-cells = < 0x1 >;      /* in zephyr/dts/x86/intel/panther_lake_h.dtsi:336 */
			status = "disabled";       /* in zephyr/dts/x86/intel/panther_lake_h.dtsi:337 */
			phandle = < 0x9 >;         /* in zephyr/dts/x86/intel/panther_lake_h.dtsi:349 */
		};

		/* node '/pcie0/uart1' defined in zephyr/dts/x86/intel/panther_lake_h.dtsi:340 */
		uart1: uart1 {
			compatible = "ns16550";                /* in zephyr/dts/x86/intel/panther_lake_h.dtsi:341 */
			vendor-id = < 0x8086 >;                /* in zephyr/dts/x86/intel/panther_lake_h.dtsi:342 */
			device-id = < 0xe426 >;                /* in zephyr/dts/x86/intel/panther_lake_h.dtsi:343 */
			reg-shift = < 0x2 >;                   /* in zephyr/dts/x86/intel/panther_lake_h.dtsi:344 */
			clock-frequency = < 0x1c2000 >;        /* in zephyr/dts/x86/intel/panther_lake_h.dtsi:345 */
			interrupts = < 0xfffffff 0xa100 0x3 >; /* in zephyr/dts/x86/intel/panther_lake_h.dtsi:346 */
			interrupt-parent = < &intc >;          /* in zephyr/dts/x86/intel/panther_lake_h.dtsi:347 */
			current-speed = < 0x1c200 >;           /* in zephyr/dts/x86/intel/panther_lake_h.dtsi:348 */
			dmas = < &uart1_dma 0x0 >,
			       < &uart1_dma 0x1 >;             /* in zephyr/dts/x86/intel/panther_lake_h.dtsi:349 */
			dma-names = "tx",
			            "rx";                      /* in zephyr/dts/x86/intel/panther_lake_h.dtsi:350 */
			status = "disabled";                   /* in zephyr/dts/x86/intel/panther_lake_h.dtsi:351 */
		};

		/* node '/pcie0/uart2' defined in zephyr/dts/x86/intel/panther_lake_h.dtsi:354 */
		uart2: uart2 {
			compatible = "ns16550";                /* in zephyr/dts/x86/intel/panther_lake_h.dtsi:355 */
			vendor-id = < 0x8086 >;                /* in zephyr/dts/x86/intel/panther_lake_h.dtsi:356 */
			device-id = < 0xe452 >;                /* in zephyr/dts/x86/intel/panther_lake_h.dtsi:357 */
			reg-shift = < 0x2 >;                   /* in zephyr/dts/x86/intel/panther_lake_h.dtsi:358 */
			clock-frequency = < 0x1c2000 >;        /* in zephyr/dts/x86/intel/panther_lake_h.dtsi:359 */
			interrupts = < 0xfffffff 0xa100 0x3 >; /* in zephyr/dts/x86/intel/panther_lake_h.dtsi:360 */
			interrupt-parent = < &intc >;          /* in zephyr/dts/x86/intel/panther_lake_h.dtsi:361 */
			current-speed = < 0x1c200 >;           /* in zephyr/dts/x86/intel/panther_lake_h.dtsi:362 */
			status = "disabled";                   /* in zephyr/dts/x86/intel/panther_lake_h.dtsi:363 */
		};
	};

	/* node '/soc' defined in zephyr/dts/x86/intel/panther_lake_h.dtsi:367 */
	soc {
		#address-cells = < 0x1 >;  /* in zephyr/dts/x86/intel/panther_lake_h.dtsi:368 */
		#size-cells = < 0x1 >;     /* in zephyr/dts/x86/intel/panther_lake_h.dtsi:369 */
		compatible = "simple-bus"; /* in zephyr/dts/x86/intel/panther_lake_h.dtsi:370 */
		ranges;                    /* in zephyr/dts/x86/intel/panther_lake_h.dtsi:371 */

		/* node '/soc/vtd@fed91000' defined in zephyr/dts/x86/intel/panther_lake_h.dtsi:373 */
		vtd: vtd@fed91000 {
			compatible = "intel,vt-d";   /* in zephyr/dts/x86/intel/panther_lake_h.dtsi:374 */
			reg = < 0xfed91000 0x1000 >; /* in zephyr/dts/x86/intel/panther_lake_h.dtsi:375 */
			status = "okay";             /* in zephyr/dts/x86/intel/panther_lake_h.dtsi:376 */
		};

		/* node '/soc/uart@3f8' defined in zephyr/dts/x86/intel/panther_lake_h.dtsi:379 */
		uart_ec_0: uart@3f8 {
			compatible = "ns16550";         /* in zephyr/dts/x86/intel/panther_lake_h.dtsi:380 */
			reg = < 0x3f8 0x100 >;          /* in zephyr/dts/x86/intel/panther_lake_h.dtsi:381 */
			clock-frequency = < 0x1c2000 >; /* in zephyr/dts/x86/intel/panther_lake_h.dtsi:383 */
			interrupts = < 0x4 0x100 0x3 >; /* in zephyr/dts/x86/intel/panther_lake_h.dtsi:384 */
			interrupt-parent = < &intc >;   /* in zephyr/dts/x86/intel/panther_lake_h.dtsi:385 */
			reg-shift = < 0x0 >;            /* in zephyr/dts/x86/intel/panther_lake_h.dtsi:386 */
			io-mapped;                      /* in zephyr/dts/x86/intel/panther_lake_h.dtsi:387 */
			status = "okay";                /* in zephyr/boards/intel/ptl/intel_ptl_h_crb.dts:32 */
		};

		/* node '/soc/pwm@5d0000' defined in zephyr/dts/x86/intel/panther_lake_h.dtsi:391 */
		pwm0: pwm@5d0000 {
			compatible = "intel,blinky-pwm"; /* in zephyr/dts/x86/intel/panther_lake_h.dtsi:392 */
			reg = < 0x5d0000 0x500 >;        /* in zephyr/dts/x86/intel/panther_lake_h.dtsi:393 */
			reg-upper32 = < 0x40 >;          /* in zephyr/dts/x86/intel/panther_lake_h.dtsi:394 */
			reg-offset = < 0x434 >;          /* in zephyr/dts/x86/intel/panther_lake_h.dtsi:395 */
			clock-frequency = < 0x8000 >;    /* in zephyr/dts/x86/intel/panther_lake_h.dtsi:396 */
			max-pins = < 0x1 >;              /* in zephyr/dts/x86/intel/panther_lake_h.dtsi:397 */
			#pwm-cells = < 0x2 >;            /* in zephyr/dts/x86/intel/panther_lake_h.dtsi:398 */
			status = "okay";                 /* in zephyr/boards/intel/ptl/intel_ptl_h_crb.dts:52 */
		};

		/* node '/soc/mfd@70' defined in zephyr/dts/x86/intel/panther_lake_h.dtsi:402 */
		mfd: mfd@70 {
			compatible = "motorola,mc146818-mfd";          /* in zephyr/dts/x86/intel/panther_lake_h.dtsi:403 */
			reg = < 0x70 0x1 0x71 0x1 0x72 0x1 0x73 0x1 >; /* in zephyr/dts/x86/intel/panther_lake_h.dtsi:404 */
			status = "okay";                               /* in zephyr/boards/intel/ptl/intel_ptl_h_crb.dts:40 */

			/* node '/soc/mfd@70/rtc' defined in zephyr/dts/x86/intel/panther_lake_h.dtsi:406 */
			rtc: counter: rtc {
				compatible = "motorola,mc146818"; /* in zephyr/dts/x86/intel/panther_lake_h.dtsi:407 */
				interrupts = < 0x8 0x100 0x3 >;   /* in zephyr/dts/x86/intel/panther_lake_h.dtsi:408 */
				interrupt-parent = < &intc >;     /* in zephyr/dts/x86/intel/panther_lake_h.dtsi:409 */
				alarms-count = < 0x1 >;           /* in zephyr/dts/x86/intel/panther_lake_h.dtsi:410 */
				status = "okay";                  /* in zephyr/boards/intel/ptl/intel_ptl_h_crb.dts:36 */
			};

			/* node '/soc/mfd@70/bbram' defined in zephyr/dts/x86/intel/panther_lake_h.dtsi:415 */
			bbram: bbram {
				compatible = "motorola,mc146818-bbram"; /* in zephyr/dts/x86/intel/panther_lake_h.dtsi:416 */
				size = < 0xf1 >;                        /* in zephyr/dts/x86/intel/panther_lake_h.dtsi:417 */
				status = "disabled";                    /* in zephyr/dts/x86/intel/panther_lake_h.dtsi:418 */
			};
		};

		/* node '/soc/tgpio@fe001200' defined in zephyr/dts/x86/intel/panther_lake_h.dtsi:424 */
		tgpio: tgpio@fe001200 {
			compatible = "intel,timeaware-gpio"; /* in zephyr/dts/x86/intel/panther_lake_h.dtsi:425 */
			reg = < 0xfe001200 0x100 >;          /* in zephyr/dts/x86/intel/panther_lake_h.dtsi:426 */
			timer-clock = < 0x124f800 >;         /* in zephyr/dts/x86/intel/panther_lake_h.dtsi:427 */
			max-pins = < 0x2 >;                  /* in zephyr/dts/x86/intel/panther_lake_h.dtsi:428 */
			artv-ctrl;                           /* in zephyr/dts/x86/intel/panther_lake_h.dtsi:429 */
			status = "disabled";                 /* in zephyr/dts/x86/intel/panther_lake_h.dtsi:430 */
		};

		/* node '/soc/hpet@fed00000' defined in zephyr/dts/x86/intel/panther_lake_h.dtsi:433 */
		hpet: hpet@fed00000 {
			compatible = "intel,hpet";    /* in zephyr/dts/x86/intel/panther_lake_h.dtsi:434 */
			reg = < 0xfed00000 0x400 >;   /* in zephyr/dts/x86/intel/panther_lake_h.dtsi:435 */
			interrupts = < 0x2 0x0 0x4 >; /* in zephyr/dts/x86/intel/panther_lake_h.dtsi:436 */
			interrupt-parent = < &intc >; /* in zephyr/dts/x86/intel/panther_lake_h.dtsi:437 */
			status = "disabled";          /* in zephyr/dts/x86/intel/panther_lake_h.dtsi:438 */
		};

		/* node '/soc/tco_wdt@400' defined in zephyr/dts/x86/intel/panther_lake_h.dtsi:441 */
		tco_wdt: tco_wdt@400 {
			compatible = "intel,tco-wdt"; /* in zephyr/dts/x86/intel/panther_lake_h.dtsi:442 */
			reg = < 0x400 0x20 >;         /* in zephyr/dts/x86/intel/panther_lake_h.dtsi:443 */
			status = "okay";              /* in zephyr/boards/intel/ptl/intel_ptl_h_crb.dts:48 */
		};
	};
};
